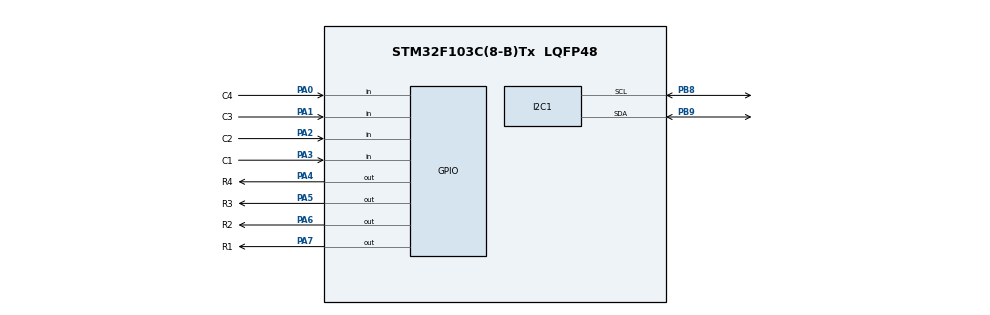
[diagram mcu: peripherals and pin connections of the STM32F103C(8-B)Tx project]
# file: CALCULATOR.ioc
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Mcu.Family=STM32F1
Mcu.Name=STM32F103C(8-B)Tx
Mcu.Package=LQFP48
NVIC.PriorityGroup=NVIC_PRIORITYGROUP_4
PA0-WKUP.GPIO_Label=C4
PA0-WKUP.GPIO_PuPd=GPIO_PULLUP
PA0-WKUP.Signal=GPIO_Input
PA1.GPIO_Label=C3
PA1.GPIO_PuPd=GPIO_PULLUP
PA1.Signal=GPIO_Input
PA13.Mode=Serial_Wire
PA13.Signal=SYS_JTMS-SWDIO
PA14.Mode=Serial_Wire
PA14.Signal=SYS_JTCK-SWCLK
PA2.GPIO_Label=C2
PA2.GPIO_PuPd=GPIO_PULLUP
PA2.Signal=GPIO_Input
PA3.GPIO_Label=C1
PA3.GPIO_PuPd=GPIO_PULLUP
PA3.Signal=GPIO_Input
PA4.GPIO_Label=R4
PA4.GPIO_PuPd=GPIO_PULLDOWN
PA4.Signal=GPIO_Output
PA5.GPIO_Label=R3
PA5.GPIO_PuPd=GPIO_PULLDOWN
PA5.Signal=GPIO_Output
PA6.GPIO_Label=R2
PA6.GPIO_PuPd=GPIO_PULLDOWN
PA6.Signal=GPIO_Output
PA7.GPIO_Label=R1
PA7.GPIO_PuPd=GPIO_PULLDOWN
PA7.Signal=GPIO_Output
PB8.Mode=I2C
PB8.Signal=I2C1_SCL
PB9.Mode=I2C
PB9.Signal=I2C1_SDA
ProjectManager.HeapSize=0x200
ProjectManager.StackSize=0x400
ProjectManager.TargetToolchain=STM32CubeIDE
RCC.APB1Freq_Value=8000000
RCC.APB2Freq_Value=8000000
board=custom

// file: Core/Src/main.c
/* USER CODE BEGIN Header */
/**
  ******************************************************************************
  * @file           : main.c
  * @brief          : Main program body
  ******************************************************************************
  * @attention
  *
  * Copyright (c) 2023 STMicroelectronics.
  * All rights reserved.
  *
  * This software is licensed under terms that can be found in the LICENSE file
  * in the root directory of this software component.
  * If no LICENSE file comes with this software, it is provided AS-IS.
  *
  ******************************************************************************
  */
/* USER CODE END Header */
#include "main.h"
#include "string.h"

/* USER CODE BEGIN Includes */
#include "keypad_4x4.h"
#include "liquidcrystal_i2c.h"
#include "stdio.h"
/* USER CODE END Includes */

I2C_HandleTypeDef hi2c1;

/* USER CODE BEGIN PV */
char key;
char operand1[16] = ""; // Buffer for the first operand
char operand2[16] = ""; // Buffer for the second operand
char result[16] = "";   // Buffer for the result
char operator = '\0';   // Variable to store the operator
/* USER CODE END PV */

void SystemClock_Config(void);
static void MX_GPIO_Init(void);
static void MX_I2C1_Init(void);

#define LCD_ROWS 2
int main(void)
{

  /* MCU Configuration--------------------------------------------------------*/

  /* Reset of all peripherals, Initializes the Flash interface and the Systick. */
  HAL_Init();

  /* Configure the system clock */
  SystemClock_Config();

  /* Initialize all configured peripherals */
  MX_GPIO_Init();
  MX_I2C1_Init();
  /* USER CODE BEGIN 2 */
  HD44780_Init(LCD_ROWS);
  // Display "Calculator" at the second row, third column
  HD44780_PrintStr("___Calculator___");
  HD44780_SetCursor(2, 5);
  // Wait for 1500 milliseconds
  HAL_Delay(1500);
  // Clear the LCD
  HD44780_Clear();
  /* USER CODE END 2 */

  /* Infinite loop */
  while (1)
  {
    // Get a character from the keypad
    key = Keypad_Get_Char();
    if (key != '\0') {
      if (key >= '0' && key <= '9') {
        // Numeric key, append to the operand buffer
        if (operator == '\0') {
          strcat(operand1, &key);
        } else {
          strcat(operand2, &key);
        }
      } else if (key == '+' || key == '-' || key == '*' || key == '/') {
        // Operator key
        operator = key;
      } else if (key == '=') {
        // Equals key, perform calculation
        int num1 = atoi(operand1);
        int num2 = atoi(operand2);
        int resultVal;
        switch (operator) {
          case '+':
            resultVal = num1 + num2;
            break;
          case '-':
            resultVal = num1 - num2;
            break;
          case '*':
            resultVal = num1 * num2;
            break;
          case '/':
            if (num2 != 0) {
              resultVal = num1 / num2;
            } else {
              // Handle division by zero error
              strcpy(result, "Error");
              HD44780_SetCursor(1, 1);
              HD44780_PrintStr(result);
              HAL_Delay(2000);
              // Clear buffers
              strcpy(operand1, "");
              strcpy(operand2, "");
              strcpy(result, "");
              operator = '\0';
              HD44780_Clear();
              continue;
            }
            break;
        }
        // Convert the result to a string and display
        sprintf(result, "%d", resultVal);
        HD44780_SetCursor(1, 1);
        HD44780_PrintStr(result);
        HAL_Delay(2000);
        // Clear buffers
        strcpy(operand1, "");
        strcpy(operand2, "");
        strcpy(result, "");
        operator = '\0';
        HD44780_Clear();
      } else if (key == 'C') {
        // Clear key, clear all buffers and the display
        strcpy(operand1, "");
        strcpy(operand2, "");
        strcpy(result, "");
        operator = '\0';
        HD44780_Clear();
      }
      // Display the current state on the LCD
      HD44780_SetCursor(1, 1);
      HD44780_PrintStr(operand1);

      if (operator != '\0') {
        HD44780_SetCursor(1, 2);
        HD44780_PrintStr(&operator);
        HD44780_SetCursor(1, 3);
        HD44780_PrintStr(operand2);
      }
    }
  }
}

void SystemClock_Config(void)
{
  RCC_OscInitTypeDef RCC_OscInitStruct = {0};
  RCC_ClkInitTypeDef RCC_ClkInitStruct = {0};

  /** Initializes the RCC Oscillators according to the specified parameters
  * in the RCC_OscInitTypeDef structure.
  */
  RCC_OscInitStruct.OscillatorType = RCC_OSCILLATORTYPE_HSI;
  RCC_OscInitStruct.HSIState = RCC_HSI_ON;
  RCC_OscInitStruct.HSICalibrationValue = RCC_HSICALIBRATION_DEFAULT;
  RCC_OscInitStruct.PLL.PLLState = RCC_PLL_NONE;
  if (HAL_RCC_OscConfig(&RCC_OscInitStruct) != HAL_OK)
  {
    Error_Handler();
  }

  /** Initializes the CPU, AHB and APB buses clocks
  */
  RCC_ClkInitStruct.ClockType = RCC_CLOCKTYPE_HCLK|RCC_CLOCKTYPE_SYSCLK
                              |RCC_CLOCKTYPE_PCLK1|RCC_CLOCKTYPE_PCLK2;
  RCC_ClkInitStruct.SYSCLKSource = RCC_SYSCLKSOURCE_HSI;
  RCC_ClkInitStruct.AHBCLKDivider = RCC_SYSCLK_DIV1;
  RCC_ClkInitStruct.APB1CLKDivider = RCC_HCLK_DIV1;
  RCC_ClkInitStruct.APB2CLKDivider = RCC_HCLK_DIV1;

  if (HAL_RCC_ClockConfig(&RCC_ClkInitStruct, FLASH_LATENCY_0) != HAL_OK)
  {
    Error_Handler();
  }
}

static void MX_I2C1_Init(void)
{

  hi2c1.Instance = I2C1;
  hi2c1.Init.ClockSpeed = 100000;
  hi2c1.Init.DutyCycle = I2C_DUTYCYCLE_2;
  hi2c1.Init.OwnAddress1 = 0;
  hi2c1.Init.AddressingMode = I2C_ADDRESSINGMODE_7BIT;
  hi2c1.Init.DualAddressMode = I2C_DUALADDRESS_DISABLE;
  hi2c1.Init.OwnAddress2 = 0;
  hi2c1.Init.GeneralCallMode = I2C_GENERALCALL_DISABLE;
  hi2c1.Init.NoStretchMode = I2C_NOSTRETCH_DISABLE;
  if (HAL_I2C_Init(&hi2c1) != HAL_OK)
  {
    Error_Handler();
  }

}

static void MX_GPIO_Init(void)
{
  GPIO_InitTypeDef GPIO_InitStruct = {0};

  /* GPIO Ports Clock Enable */
  __HAL_RCC_GPIOA_CLK_ENABLE();
  __HAL_RCC_GPIOB_CLK_ENABLE();

  /*Configure GPIO pin Output Level */
  HAL_GPIO_WritePin(GPIOA, R4_Pin|R3_Pin|R2_Pin|R1_Pin, GPIO_PIN_RESET);

  /*Configure GPIO pins : C4_Pin C3_Pin C2_Pin C1_Pin */
  GPIO_InitStruct.Pin = C4_Pin|C3_Pin|C2_Pin|C1_Pin;
  GPIO_InitStruct.Mode = GPIO_MODE_INPUT;
  GPIO_InitStruct.Pull = GPIO_PULLUP;
  HAL_GPIO_Init(GPIOA, &GPIO_InitStruct);

  /*Configure GPIO pins : R4_Pin R3_Pin R2_Pin R1_Pin */
  GPIO_InitStruct.Pin = R4_Pin|R3_Pin|R2_Pin|R1_Pin;
  GPIO_InitStruct.Mode = GPIO_MODE_OUTPUT_PP;
  GPIO_InitStruct.Pull = GPIO_PULLDOWN;
  GPIO_InitStruct.Speed = GPIO_SPEED_FREQ_LOW;
  HAL_GPIO_Init(GPIOA, &GPIO_InitStruct);

}

void Error_Handler(void)
{
  __disable_irq();
  while (1)
  {
  }
}
